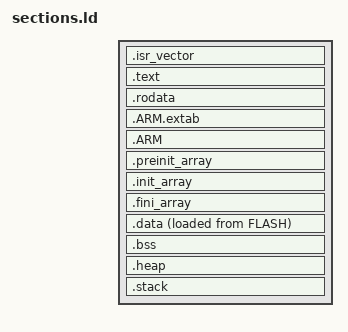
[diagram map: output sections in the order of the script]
/*
 * Shared SECTIONS layout for every Cortex-M target.
 *
 * Each per-target linker script (esc60_g431.ld, esc80_g474.ld, ...) only
 * defines the MEMORY map and then `INCLUDE`s this file.
 */

ENTRY(Reset_Handler)

_estack = ORIGIN(RAM) + LENGTH(RAM);

SECTIONS
{
    .isr_vector :
    {
        . = ALIGN(4);
        KEEP(*(.isr_vector))
        . = ALIGN(4);
    } > FLASH

    .text :
    {
        . = ALIGN(4);
        *(.text)
        *(.text*)
        *(.glue_7) *(.glue_7t)
        *(.eh_frame)
        KEEP (*(.init))
        KEEP (*(.fini))
        . = ALIGN(4);
        _etext = .;
    } > FLASH

    .rodata :
    {
        . = ALIGN(4);
        *(.rodata)
        *(.rodata*)
        . = ALIGN(4);
    } > FLASH

    .ARM.extab : { *(.ARM.extab* .gnu.linkonce.armextab.*) } > FLASH
    .ARM       : { __exidx_start = .; *(.ARM.exidx*) __exidx_end = .; } > FLASH

    .preinit_array : { PROVIDE_HIDDEN(__preinit_array_start = .); KEEP(*(.preinit_array*)) PROVIDE_HIDDEN(__preinit_array_end = .); } > FLASH
    .init_array    : { PROVIDE_HIDDEN(__init_array_start = .); KEEP(*(SORT(.init_array.*))) KEEP(*(.init_array*)) PROVIDE_HIDDEN(__init_array_end = .); } > FLASH
    .fini_array    : { PROVIDE_HIDDEN(__fini_array_start = .); KEEP(*(SORT(.fini_array.*))) KEEP(*(.fini_array*)) PROVIDE_HIDDEN(__fini_array_end = .); } > FLASH

    _sidata = LOADADDR(.data);
    .data :
    {
        . = ALIGN(4);
        _sdata = .;
        *(.data)
        *(.data*)
        . = ALIGN(4);
        _edata = .;
    } > RAM AT > FLASH

    .bss :
    {
        . = ALIGN(4);
        _sbss = .;
        __bss_start__ = _sbss;
        *(.bss)
        *(.bss*)
        *(COMMON)
        . = ALIGN(4);
        _ebss = .;
        __bss_end__ = _ebss;
    } > RAM

    .heap (NOLOAD) :
    {
        . = ALIGN(8);
        _end = .;
        end = _end;
        . = . + 0x400;
        _eheap = .;
    } > RAM

    .stack (NOLOAD) :
    {
        . = ALIGN(8);
        . = . + 0x400;
    } > RAM
}
